# SPGSS2_1.0 register map
Vendor: Texas Instruments
Registers are 32-bit, read-write, no defined reset value unless marked. A register's access mark holds for its fields unless they carry their own. Offsets are as the file gives them; [hi:lo] are bit positions; lines under a group give offsets from that group; {n}, {i} and the like mark numbered series; 'fields as' and 'values as' point back to an identical list; <NAME> marks a mode.

## SPGSS2 (part 2 of 4)
0x7020 SPGSS2_UC3_UART_IPSTANDARD_CPU_INT group
  0x00 SPGSS2_UC3_UART_IPSTANDARD_IIDX ro — Interrupt index
    [7:0] STAT — UART Module Interrupt Vector Value. This register provides the highes priority interrupt index. A read clears the corresponding interrupt flag in RIS and MIS registers. 15h-1Fh = Reserved
      0=NO_INTR (No interrupt pending); 1=RTFG (UART receive time-out interrupt; Interrupt Flag: RT; Interrupt Priority: Highest); 2=FEFG (UART framing error interrupt; Interrupt Flag: FE); 3=PEFG (UART parity error interrupt; Interrupt Flag: PE); 4=BEFG (UART break error interrupt; Interrupt Flag: BE); 5=OEFG (UART receive overrun error interrupt; Interrupt Flag: OE); 6=RXNE (Negative edge on UARTxRXD interrupt; Interrupt Flag: RXNE); 7=RXPE (Positive edge on UARTxRXD interrupt; Interrupt Flag: RXPE); 8=LINC0 (LIN capture 0 / match interrupt; Interrupt Flag: LINC0); 9=LINC1 (LIN capture 1 interrupt; Interrupt Flag: LINC1); 10=LINOVF (LIN hardware counter overflow interrupt; Interrupt Flag: LINOVF); 11=RXIFG (UART receive interrupt; Interrupt Flag: RX); 12=TXIFG (UART transmit interrupt; Interrupt Flag: TX); 13=EOT (UART end of transmission interrupt (transmit serializer empty); Interrupt Flag: EOT); 14=ADDR_MATCH (9-bit mode address match interrupt; Interrupt Flag: ADDR_MATCH); 15=CTS (UART Clear to Send Modem interrupt; Interrupt Flag: CTS); 16=DMA_DONE_RX (DMA DONE on RX); 17=DMA_DONE_TX (DMA DONE on TX); 18=NERR_EVT (Noise Error Event); 19=DMA_PREIRQ_RX (DMA PRE IRQ INTERRUPT); 20=DMA_PREIRQ_TX (DMA PRE IRQ INTERRUPT); 21=LTFG (UART line time-out interrupt; Interrupt Flag)
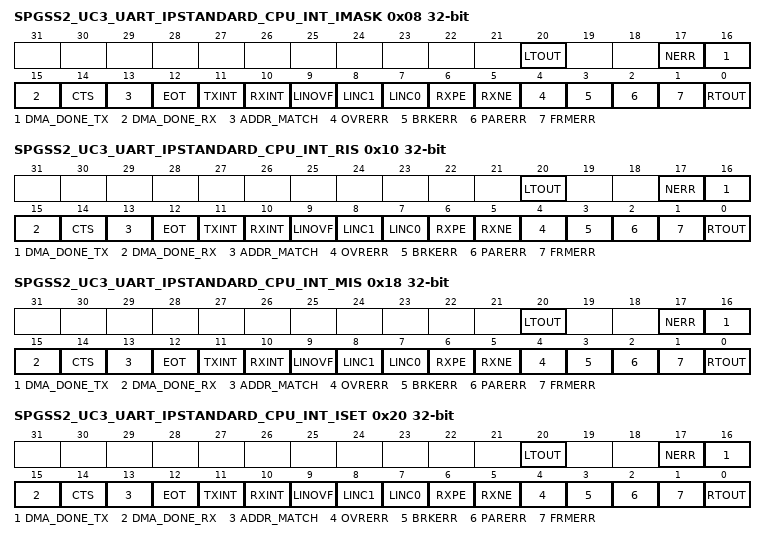
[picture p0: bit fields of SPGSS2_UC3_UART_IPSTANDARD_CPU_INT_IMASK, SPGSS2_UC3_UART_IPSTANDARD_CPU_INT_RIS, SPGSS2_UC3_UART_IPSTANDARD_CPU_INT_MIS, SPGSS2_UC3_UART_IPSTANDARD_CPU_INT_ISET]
  0x08 SPGSS2_UC3_UART_IPSTANDARD_CPU_INT_IMASK — Interrupt mask
    [20] LTOUT — Enable UARTOUT Line Time-Out Interrupt.
      0=CLR (Clear Interrupt Mask); 1=SET (Set Interrupt Mask)
    [17] NERR — Noise Error on triple voting. Asserted when the 3 samples of majority voting are not equal
      0=CLR (Clear Interrupt Mask); 1=SET (Set Interrupt Mask)
    [16] DMA_DONE_TX — Enable DMA Done on TX Event Channel Interrupt
      0=CLR (Interrupt disabled); 1=SET (Set Interrupt Mask)
    [15] DMA_DONE_RX — Enable DMA Done on RX Event Channel Interrupt
      0=CLR (Interrupt disabled); 1=SET (Set Interrupt Mask)
    [14] CTS — Enable UART Clear to Send Modem Interrupt.
      0=CLR (Interrupt disabled); 1=SET (Set Interrupt Mask)
    [13] ADDR_MATCH — Enable Address Match Interrupt.
      0=CLR (Clear Interrupt Mask); 1=SET (Set Interrupt Mask)
    [12] EOT — Enable UART End of Transmission Interrupt Indicates that the last bit of all transmitted data and flags has left the serializer and without any further Data in the TX Fifo or Buffer.
      0=CLR (Clear Interrupt Mask); 1=SET (Set Interrupt Mask)
    [11] TXINT — Enable UART Transmit Interrupt.
      0=CLR (Clear Interrupt Mask); 1=SET (Set Interrupt Mask)
    [10] RXINT — Enable UART Receive Interrupt.
      0=CLR (Clear Interrupt Mask); 1=SET (Set Interrupt Mask)
    [9] LINOVF — Enable LIN Hardware Counter Overflow Interrupt.
      0=CLR (Clear Interrupt Mask); 1=SET (Set Interrupt Mask)
    [8] LINC1 — Enable LIN Capture 1 Interrupt.
      0=CLR (Clear Interrupt Mask); 1=SET (Set Interrupt Mask)
    [7] LINC0 — Enable LIN Capture 0 / Match Interrupt .
      0=CLR (Clear Interrupt Mask); 1=SET (Set Interrupt Mask)
    [6] RXPE — Enable Positive Edge on UARTxRXD Interrupt.
      0=CLR (Clear Interrupt Mask); 1=SET (Set Interrupt Mask)
    [5] RXNE — Enable Negative Edge on UARTxRXD Interrupt.
      0=CLR (Clear Interrupt Mask); 1=SET (Set Interrupt Mask)
    [4] OVRERR — Enable UART Receive Overrun Error Interrupt.
      0=CLR (Clear Interrupt Mask); 1=SET (Set Interrupt Mask)
    [3] BRKERR — Enable UART Break Error Interrupt.
      0=CLR (Clear Interrupt Mask); 1=SET (Set Interrupt Mask)
    [2] PARERR — Enable UART Parity Error Interrupt.
      0=CLR (Clear Interrupt Mask); 1=SET (Set Interrupt Mask)
    [1] FRMERR — Enable UART Framing Error Interrupt.
      0=CLR (Clear Interrupt Mask); 1=SET (Set Interrupt Mask)
    [0] RTOUT — Enable UARTOUT Receive Time-Out Interrupt.
      0=CLR (Clear Interrupt Mask); 1=SET (Set Interrupt Mask)
  0x10 SPGSS2_UC3_UART_IPSTANDARD_CPU_INT_RIS — Raw interrupt status
    [20] LTOUT — UARTOUT Line Time-Out Interrupt. Set: no start edge has been detected for an additional character period after reception of last character. This is irrespective of FIFO contents Clear: timeout has not occured
      0=CLR (Interrupt did not occur); 1=SET (Interrupt occurred)
    [17] NERR — Noise Error on triple voting. Asserted when the 3 samples of majority voting are not equal
      0=CLR (Interrupt did not occur); 1=SET (Interrupt occurred)
    [16] DMA_DONE_TX — DMA Done on TX Event Channel Interrupt
      0=CLR (Interrupt disabled); 1=SET (Interrupt occurred)
    [15] DMA_DONE_RX — DMA Done on RX Event Channel Interrupt
      0=CLR (Interrupt disabled); 1=SET (Interrupt occurred)
    [14] CTS — UART Clear to Send Modem Interrupt. This interrupt is raised when CTS toggles, either from '0' to '1' or from '1' to '0'.
      0=CLR (Interrupt disabled); 1=SET (Interrupt occurred)
    [13] ADDR_MATCH — Address Match Interrupt.
      0=CLR (Interrupt did not occur); 1=SET (Interrupt occurred)
    [12] EOT — UART End of Transmission Interrupt Indicates that the last bit of all transmitted data and flags has left the serializer and without any further Data in the TX Fifo or Buffer.
      0=CLR (Interrupt did not occur); 1=SET (Interrupt occurred)
    [11] TXINT — UART Transmit Interrupt.
      0=CLR (Interrupt did not occur); 1=SET (Interrupt occurred)
    [10] RXINT — UART Receive Interrupt.
      0=CLR (Interrupt did not occur); 1=SET (Interrupt occurred)
    [9] LINOVF — LIN Hardware Counter Overflow Interrupt.
      0=CLR (Interrupt did not occur); 1=SET (Interrupt occurred)
    [8] LINC1 — LIN Capture 1 Interrupt.
      0=CLR (Interrupt did not occur); 1=SET (Interrupt occurred)
    [7] LINC0 — LIN Capture 0 / Match Interrupt .
      0=CLR (Interrupt did not occur); 1=SET (Interrupt occurred)
    [6] RXPE — Positive Edge on UARTxRXD Interrupt.
      0=CLR (Interrupt did not occur); 1=SET (Interrupt occurred)
    [5] RXNE — Negative Edge on UARTxRXD Interrupt.
      0=CLR (Interrupt did not occur); 1=SET (Interrupt occurred)
    [4] OVRERR — UART Receive Overrun Error Interrupt. UART Receive Overrun Error Interrupt is raised when the receive FIFO is flow and a new frame is received
      0=CLR (Interrupt did not occur); 1=SET (Interrupt occurred)
    [3] BRKERR — UART Break Error Interrupt. Break Error Interrupt is raised when all data bits, parity bit and stop bits are '0'
      0=CLR (Interrupt did not occur); 1=SET (Interrupt occurred)
    [2] PARERR — UART Parity Error Interrupt.
      0=CLR (Interrupt did not occur); 1=SET (Interrupt occurred)
    [1] FRMERR — UART Framing Error Interrupt. Framing error interrupt is raised when a "low" stop bit is detected.
      0=CLR (Interrupt did not occur); 1=SET (Interrupt occurred)
    [0] RTOUT — UARTOUT Receive Time-Out Interrupt. Interupt is raised when a time-out has lapsed and there are still items in the FIFO
      0=CLR (Interrupt did not occur); 1=SET (Interrupt occurred)
  0x18 SPGSS2_UC3_UART_IPSTANDARD_CPU_INT_MIS — Masked interrupt status
    [all] fields
      0=CLR (Interrupt did not occur); 1=SET (Interrupt occurred)
    [20] LTOUT — Masked UARTOUT Line Time-Out Interrupt.
    [17] NERR — Noise Error on triple voting. Asserted when the 3 samples of majority voting are not equal
    [16] DMA_DONE_TX — Masked DMA Done on TX Event Channel Interrupt
    [15] DMA_DONE_RX — Masked DMA Done on RX Event Channel Interrupt
    [14] CTS — Masked UART Clear to Send Modem Interrupt.
    [13] ADDR_MATCH — Masked Address Match Interrupt.
    [12] EOT — UART End of Transmission Interrupt Indicates that the last bit of all transmitted data and flags has left the serializer and without any further Data in the TX Fifo or Buffer.
    [11] TXINT — Masked UART Transmit Interrupt.
    [10] RXINT — Masked UART Receive Interrupt.
    [9] LINOVF — Masked LIN Hardware Counter Overflow Interrupt.
    [8] LINC1 — Masked LIN Capture 1 Interrupt.
    [7] LINC0 — Masked LIN Capture 0 / Match Interrupt .
    [6] RXPE — Masked Positive Edge on UARTxRXD Interrupt.
    [5] RXNE — Masked Negative Edge on UARTxRXD Interrupt.
    [4] OVRERR — Masked UART Receive Overrun Error Interrupt.
    [3] BRKERR — Masked UART Break Error Interrupt.
    [2] PARERR — Masked UART Parity Error Interrupt.
    [1] FRMERR — Masked UART Framing Error Interrupt.
    [0] RTOUT — Masked UARTOUT Receive Time-Out Interrupt.
  0x20 SPGSS2_UC3_UART_IPSTANDARD_CPU_INT_ISET — Interrupt set
    [20] LTOUT — Set UARTOUT Line Time-Out Interrupt.
      0=NO_EFFECT (Writing 0 has no effect); 1=SET (Set Interrupt)
    [17] NERR — Noise Error on triple voting. Asserted when the 3 samples of majority voting are not equal
      0=NO_EFFECT (Writing this has no effect); 1=SET (Set the interrupt)
    [16] DMA_DONE_TX — Set DMA Done on TX Event Channel Interrupt
      0=NO_EFFECT (Interrupt disabled); 1=SET (Set Interrupt)
    [15] DMA_DONE_RX — Set DMA Done on RX Event Channel Interrupt
      0=NO_EFFECT (Interrupt disabled); 1=SET (Set Interrupt)
    [14] CTS — Set UART Clear to Send Modem Interrupt.
      0=NO_EFFECT (Writing 0 has no effect); 1=SET (Set Interrupt)
    [13] ADDR_MATCH — Set Address Match Interrupt.
      0=NO_EFFECT (Writing 0 has no effect); 1=SET (Set Interrupt)
    [12] EOT — Set UART End of Transmission Interrupt Indicates that the last bit of all transmitted data and flags has left the serializer and without any further Data in the TX Fifo or Buffer.
      0=NO_EFFECT (Writing 0 has no effect); 1=SET (Set Interrupt)
    [11] TXINT — Set UART Transmit Interrupt.
      0=NO_EFFECT (Writing 0 has no effect); 1=SET (Set Interrupt)
    [10] RXINT — Set UART Receive Interrupt.
      0=NO_EFFECT (Writing 0 has no effect); 1=SET (Set Interrupt)
    [9] LINOVF — Set LIN Hardware Counter Overflow Interrupt.
      0=NO_EFFECT (Writing 0 has no effect); 1=SET (Set Interrupt)
    [8] LINC1 — Set LIN Capture 1 Interrupt.
      0=NO_EFFECT (Writing 0 has no effect); 1=SET (Set Interrupt)
    [7] LINC0 — Set LIN Capture 0 / Match Interrupt .
      0=NO_EFFECT (Writing 0 has no effect); 1=SET (Set Interrupt)
    [6] RXPE — Set Positive Edge on UARTxRXD Interrupt.
      0=NO_EFFECT (Writing 0 has no effect); 1=SET (Set Interrupt)
    [5] RXNE — Set Negative Edge on UARTxRXD Interrupt.
      0=NO_EFFECT (Writing 0 has no effect); 1=SET (Set Interrupt)
    [4] OVRERR — Set UART Receive Overrun Error Interrupt.
      0=NO_EFFECT (Writing 0 has no effect); 1=SET (Set Interrupt)
    [3] BRKERR — Set UART Break Error Interrupt.
      0=NO_EFFECT (Writing 0 has no effect); 1=SET (Set Interrupt)
    [2] PARERR — Set UART Parity Error Interrupt.
      0=NO_EFFECT (Writing 0 has no effect); 1=SET (Set Interrupt)
    [1] FRMERR — Set UART Framing Error Interrupt.
      0=NO_EFFECT (Writing 0 has no effect); 1=SET (Set Interrupt)
    [0] RTOUT — Set UARTOUT Receive Time-Out Interrupt.
      0=NO_EFFECT (Writing 0 has no effect); 1=SET (Set Interrupt)
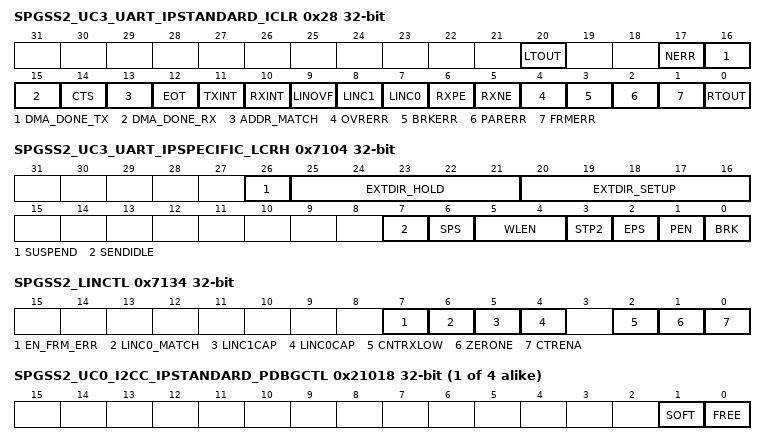
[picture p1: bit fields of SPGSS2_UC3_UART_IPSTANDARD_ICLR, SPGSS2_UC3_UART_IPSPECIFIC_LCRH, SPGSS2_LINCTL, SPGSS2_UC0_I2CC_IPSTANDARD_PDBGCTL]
  0x28 SPGSS2_UC3_UART_IPSTANDARD_ICLR — Interrupt clear
    [20] LTOUT — Clear UARTOUT Line Time-Out Interrupt.
      0=NO_EFFECT (Writing 0 has no effect); 1=CLR (Clear Interrupt)
    [17] NERR — Noise Error on triple voting. Asserted when the 3 samples of majority voting are not equal
      values as LTOUT
    [16] DMA_DONE_TX — Clear DMA Done on TX Event Channel Interrupt
      0=NO_EFFECT (Interrupt disabled); 1=CLR (Clear Interrupt)
    [15] DMA_DONE_RX — Clear DMA Done on RX Event Channel Interrupt
      0=NO_EFFECT (Interrupt disabled); 1=CLR (Clear Interrupt)
    [14] CTS — Clear UART Clear to Send Modem Interrupt.
      values as LTOUT
    [13] ADDR_MATCH — Clear Address Match Interrupt.
      values as LTOUT
    [12] EOT — Clear UART End of Transmission Interrupt Indicates that the last bit of all transmitted data and flags has left the serializer and without any further Data in the TX Fifo or Buffer.
      values as LTOUT
    [11] TXINT — Clear UART Transmit Interrupt.
      values as LTOUT
    [10] RXINT — Clear UART Receive Interrupt.
      values as LTOUT
    [9] LINOVF — Clear LIN Hardware Counter Overflow Interrupt.
      values as LTOUT
    [8] LINC1 — Clear LIN Capture 1 Interrupt.
      values as LTOUT
    [7] LINC0 — Clear LIN Capture 0 / Match Interrupt .
      values as LTOUT
    [6] RXPE — Clear Positive Edge on UARTxRXD Interrupt.
      values as LTOUT
    [5] RXNE — Clear Negative Edge on UARTxRXD Interrupt.
      values as LTOUT
    [4] OVRERR — Clear UART Receive Overrun Error Interrupt.
      values as LTOUT
    [3] BRKERR — Clear UART Break Error Interrupt.
      values as LTOUT
    [2] PARERR — Clear UART Parity Error Interrupt.
      values as LTOUT
    [1] FRMERR — Clear UART Framing Error Interrupt.
      values as LTOUT
    [0] RTOUT — Clear UARTOUT Receive Time-Out Interrupt.
      values as LTOUT
0x7104 SPGSS2_UC3_UART_IPSPECIFIC_LCRH — UART Line Control Register
  [26] SUSPEND — Suspend external communication
    0=DISABLE (Functional mode resumed); 1=ENABLE (External communication suspended)
  [25:21] EXTDIR_HOLD — Defines the number of UARTclk ticks the signal to control the external driver for the RS485 will be reset after the beginning of the stop bit. (If 2 STOP bits are enabled the beginning of the 2nd STOP bit.)
    0=MINIMUM (Smallest value); 31=MAXIMUM (Highest possible value)
  [20:16] EXTDIR_SETUP — Defines the number of UARTclk ticks the signal to control the external driver for the RS485 will be set before the START bit is send
    values as EXTDIR_HOLD
  [7] SENDIDLE — UART send IDLE pattern. When this bit is set, SENDIDLE period of 11 bit times will be sent on the TX line. Read STAT.SENDIDLE bit to readback current status of SENDIDLE
    0=DISABLE (Normal operation); 1=ENABLE (Send Idle Pattern)
  [6] SPS — UART Stick Parity Select The Stick Parity Select (SPS) bit is used to set either a permanent '1' or a permanent '0' as parity when transmitting or receiving data. Its purpose is to typically indicate the first byte of a package or to mark an address byte, for example in a multi-drop RS-485 network. When bits PEN, EPS, and SPS of UARTLCRH are set, the parity bit is transmitted and checked as a 0. When bits PEN and SPS are set and EPS is cleared, the parity bit is transmitted and checked as a 1.
    0=DISABLE (Disable Stick Parity); 1=ENABLE (Enable Stick Parity)
  [5:4] WLEN — UART Word Length The bits indicate the number of data bits transmitted or received in a frame as follows:
    0=DATABIT5 (5 bits (default)); 1=DATABIT6 (6 bits); 2=DATABIT7 (7 bits); 3=DATABIT8 (8 bits)
  [3] STP2 — UART Two Stop Bits Select When in 7816 smart card mode (the SMART bit is set in the UARTCTL register), the number of stop bits is forced to 2.
    0=DISABLE (One stop bit is transmitted at the end of a frame.); 1=ENABLE (Two stop bits are transmitted at the end of a frame. The receive logic checks for two stop bits being received and provide Frame Error if either is invalid.)
  [2] EPS — UART Even Parity Select This bit has no effect when parity is disabled by the PEN bit. For 9-Bit UART Mode transmissions, this bit controls the address byte and data byte indication (9th bit). 0 = The transferred byte is a data byte 1 = The transferred byte is an address byte
    0=ODD (Odd parity is performed, which checks for an odd number of 1s.); 1=EVEN (Even parity generation and checking is performed during transmission and reception, which checks for an even number of 1s in data and parity bits.)
  [1] PEN — UART Parity Enable
    0=DISABLE (Parity is disabled and no parity bit is added to the data frame.); 1=ENABLE (Parity checking and generation is enabled.)
  [0] BRK — UART Send Break (for LIN Protocol) 1. Break condition is sent on the line for as long as this bit is set
    0=DISABLE (Normal operation); 1=ENABLE (A low level is continually output on the UARTxTXD signal, after completing transmission of the current character. For the proper execution of the break command, software must set this bit for at least two frames (character periods).)
0x7130 SPGSS2_LINCNT — UART LIN Mode Counter Register
  [15:0] VALUE — 16 bit up counter clocked by the functional clock of the UART.
    0=MINIMUM (Smallest value); 0xFFFF=MAXIMUM (Highest possible value)
0x7134 SPGSS2_LINCTL — UART LIN Mode Control Register
  [7] EN_FRM_ERR — Enable FRAME ERROR
    0=DISABLE (Disable Frame Error Generation If STOP bit of '0' is received, then, FRAME ERROR is not generated); 1=ENABLE (Enable Frame Error Generation If STOP bit of '0' is received, then, FRAME ERROR is generated)
  [6] LINC0_MATCH — Counter Compare Match Mode When this bit is set to 1 a counter compare match with LINC0 register triggers an LINC0 interrupt when enabled.
    0=DISABLE (Counter compare match mode disabled (capture mode enabled)); 1=ENABLE (Counter compare match enabled (capture mode disabled))
  [5] LINC1CAP — Capture Counter on positive RXD Edge. When enabled the counter value is captured to LINC1 register on each positive RXD edge. A LINC1 interrupt is triggered when enabled.
    0=DISABLE (Capture counter on positive UARTxRXD edge disabled); 1=ENABLE (Capture counter on positive UARTxRXD edge enabled)
  [4] LINC0CAP — Capture Counter on negative RXD Edge. When enabled the counter value is captured to LINC0 register on each negative RXD edge. A LINC0 interrupt is triggered when enabled.
    0=DISABLE (Capture counter on negative UARTxRXD edge disabled); 1=ENABLE (Capture counter on negative UARTxRXD edge enabled)
  [2] CNTRXLOW — Count while low Signal on RXD When counter is enabled and the signal on RXD is low, the counter increments.
    0=DISABLE (Count while low Signal on UARTxRXD disabled); 1=ENABLE (Count while low Signal on UARTxRXD enabled)
  [1] ZERONE — Zero on negative Edge of RXD. When enabled the counter is set to 0 and starts counting on a negative edge of RXD
    0=DISABLE (Zero on negative edge disabled); 1=ENABLE (Zero on negative edge enabled)
  [0] CTRENA — LIN Counter Enable. LIN counter will only count when enabled.
    0=DISABLE (Counter disabled); 1=ENABLE (Counter enabled)
0x7138 SPGSS2_LINC0 — UART LIN Mode Capture 0 Register
  [15:0] DATA — 16 Bit Capture / Compare Register Captures current LINCTR value on RXD falling edge and can generate a LINC0 interrupt when capture is enabled (LINC0CAP = 1). If compare mode is enabled (LINC0_MATCH = 1), a counter match can generate a LINC0 interrupt.
    values as SPGSS2_LINCNT.VALUE
0x713C SPGSS2_LINC1 — UART LIN Mode Capture 1 Register
  [15:0] DATA — 16 Bit Capture / Compare Register Captures current LINCTR value on RXD rising edge and can generate a LINC1 interrupt when capture is enabled (LINC1CAP = 1)
    values as SPGSS2_LINCNT.VALUE
{0x21000+0x2000*i} SPGSS2_UC{i}_I2CC_IPSTANDARD_CLKDIV (i=0..3) — Clock Divider
  [2:0] RATIO — Selects divide ratio of module clock Division factor 0 : DIV_BY_1 1 : DIV_BY_2 .... 63: DIV_BY_64
{0x21008+0x2000*i} SPGSS2_UC{i}_I2CC_IPSTANDARD_CLKSEL (i=0..3) — Clock Select for Ultra Low Power peripherals
  [3] BUSCLK_SEL — Selects BUS CLK as clock source if enabled
    0=DISABLE (Does not select this clock as a source); 1=ENABLE (Select this clock as a source)
{0x21018+0x2000*i} SPGSS2_UC{i}_I2CC_IPSTANDARD_PDBGCTL (i=0..3) — Peripheral Debug Control
  [1] SOFT — Soft halt boundary control. This function is only available, if [FREE] is set to 'STOP'
    0=DEPRECATED (Not supported); 1=DELAYED (The peripheral blocks the debug freeze until it has reached a boundary where it can resume without corruption)
  [0] FREE — Free run control
    0=STOP (The peripheral freezes functionality while the Core Halted input is asserted and resumes when it is deasserted.); 1=RUN (The peripheral ignores the state of the Core Halted input)
{0x21020+0x2000*i} SPGSS2_UC{i}_I2CC_IPSTANDARD_CPU_INT group (i=0..2)
  0x00 SPGSS2_UC{i}_I2CC_IPSTANDARD_IIDX ro — Interrupt index
    [7:0] STAT — I2C Module Interrupt Vector Value. This register provides the highes priority interrupt index. A read clears the corresponding interrupt flag in RIS and MISC. 15h-1Fh = Reserved
      0=NO_INTR (No interrupt pending); 1=RXDONEFG (Data received); 2=TXDONEFG (data transmitted); 3=RXTRG (Receive Trigger); 4=TXTRG (Transmit Trigger); 5=RXFULL (RX FIFO FULL Event/interrupt pending); 6=TXEMPTY (Transmit FIFO/Buffer Empty Event/interrupt pending); 8=NACKFG (Address/Data NACK); 9=STARTFG (Start Event); 10=STOPFG (Stop Event); 11=ARBLOSTFG (Arbitration Lost); 12=PEC_RX_ERR (PEC Receive Error Event); 13=TIMEOUTA (Timeout A Event); 14=TIMEOUTB (Timeout B Event); 16=DMA_DONE_RX (DMA DONE on Channel RX); 17=DMA_DONE_TX (DMA DONE on Channel TX); 19=DMA_PREIRQ_RX (DMA PRE IRQ INTERRUPT); 20=DMA_PREIRQ_TX (DMA PRE IRQ INTERRUPT)
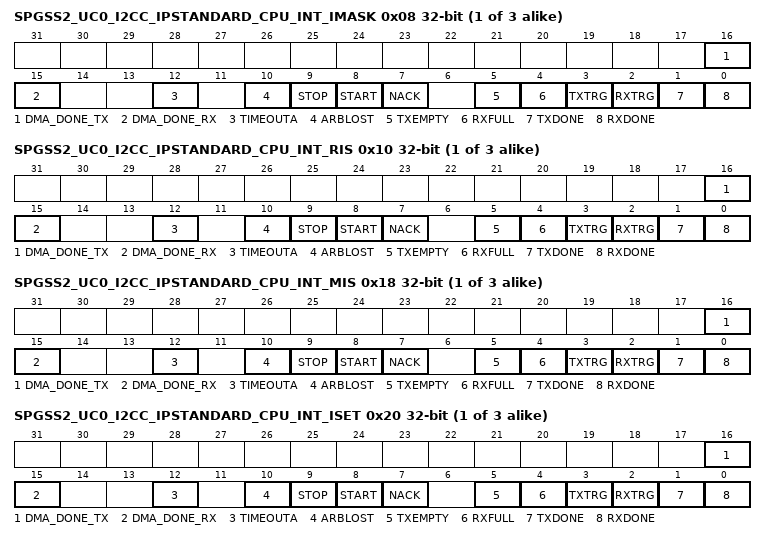
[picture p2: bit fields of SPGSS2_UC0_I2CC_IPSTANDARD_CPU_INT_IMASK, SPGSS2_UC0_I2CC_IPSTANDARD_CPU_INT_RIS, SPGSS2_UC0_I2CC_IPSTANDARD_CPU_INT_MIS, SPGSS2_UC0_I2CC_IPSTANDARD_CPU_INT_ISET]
  0x08 SPGSS2_UC{i}_I2CC_IPSTANDARD_CPU_INT_IMASK — Interrupt mask
    [16] DMA_DONE_TX — DMA Done on Event Channel TX
      0=CLR (Interrupt disabled); 1=SET (Set Interrupt Mask)
    [15] DMA_DONE_RX — DMA Done on Event Channel RX
      0=CLR (Interrupt disabled); 1=SET (Set Interrupt Mask)
    [12] TIMEOUTA — TIMEOUTA interrupt
      0=CLR (Clear Interrupt Mask); 1=SET (Set Interrupt Mask)
    [10] ARBLOST — Arbitration Lost interrupt
      0=CLR (Clear Interrupt Mask); 1=SET (Set Interrupt Mask)
    [9] STOP — STOP interrupt
      0=CLR (Clear Interrupt Mask); 1=SET (Set Interrupt Mask)
    [8] START — START interrupt
      0=CLR (Clear Interrupt Mask); 1=SET (Set Interrupt Mask)
    [7] NACK — NACK interrupt
      0=CLR (Clear Interrupt Mask); 1=SET (Set Interrupt Mask)
    [5] TXEMPTY — Transmit FIFO/Buffer Empty interrupt.
      0=CLR (Clear Interrupt Mask); 1=SET (Set Interrupt Mask)
    [4] RXFULL — RXFIFO full event
      0=CLR (Clear Interrupt Mask); 1=SET (Set Interrupt Mask)
    [3] TXTRG — Transmit Trigger
      0=CLR (Clear Interrupt Mask); 1=SET (Set Interrupt Mask)
    [2] RXTRG — Receive Trigger
      0=CLR (Clear Interrupt Mask); 1=SET (Set Interrupt Mask)
    [1] TXDONE — Transmit Transaction completed Interrupt
      0=CLR (Clear Interrupt Mask); 1=SET (Set Interrupt Mask)
    [0] RXDONE — RXDONE interrupt
      0=CLR (Clear Interrupt Mask); 1=SET (Set Interrupt Mask)
  0x10 SPGSS2_UC{i}_I2CC_IPSTANDARD_CPU_INT_RIS — Raw interrupt status
    [16] DMA_DONE_TX — DMA Done on Event Channel TX
      0=CLR (Interrupt disabled); 1=SET (Set Interrupt Mask)
    [15] DMA_DONE_RX — DMA Done on Event Channel RX
      0=CLR (Interrupt disabled); 1=SET (Set Interrupt Mask)
    [12] TIMEOUTA — Timeout A Interrupt
      0=CLR (Interrupt did not occur); 1=SET (Set Interrupt Mask)
    [10] ARBLOST — Arbitration Lost Interrupt: in multi-controller systems, when this controller loses out during arbitration
      0=CLR (Interrupt did not occur); 1=SET (Set Interrupt Mask)
    [9] STOP — STOP Detection Interrupt
      0=CLR (Interrupt did not occur); 1=SET (Set Interrupt Mask)
    [8] START — START Detection Interrupt
      0=CLR (Interrupt did not occur); 1=SET (Set Interrupt Mask)
    [7] NACK — Address/Data NACK Interrupt: set when address or data nack is received
      0=CLR (Interrupt did not occur); 1=SET (Set Interrupt Mask)
    [5] TXEMPTY — Transmit FIFO Empty: set when Transmit FIFO is empty
      0=CLR (Interrupt did not occur); 1=SET (Interrupt occured)
    [4] RXFULL — RXFIFO full event. This interrupt is set when receive FIFO is full.
      0=CLR (Interrupt did not occur); 1=SET (Interrupt occured)
    [3] TXTRG — Transmit Trigger When FIFO is present, as per IFLS settings When FIFO is not present, trigger when transmit buffer is empty
      0=CLR (Clear Interrupt Mask); 1=SET (Set Interrupt Mask)
    [2] RXTRG — Receive Trigger When FIFO is present, as per IFLS settings when FIFO is not present, this indicates when buffer is full
      0=CLR (Clear Interrupt Mask); 1=SET (Set Interrupt Mask)
    [1] TXDONE — Transmit Done Interrupt: TXDONE interrupt is raised when a burst length completes Or, in case of quick command, when a quick command with R/Wn bit set to '0'
      0=CLR (Interrupt did not occur); 1=SET (Set Interrupt Mask)
    [0] RXDONE — Receive Done Interrupt: RXDONE interrupt is raised when a burst length completes Or, in case of quick command, when a quick command with R/Wn bit set to '1'
      0=CLR (Interrupt did not occur); 1=SET (Set Interrupt Mask)
  0x18 SPGSS2_UC{i}_I2CC_IPSTANDARD_CPU_INT_MIS — Masked interrupt status
    [16] DMA_DONE_TX — DMA Done on Event Channel TX
      0=CLR (Interrupt disabled); 1=SET (Set Interrupt Mask)
    [15] DMA_DONE_RX — DMA Done on Event Channel RX
      0=CLR (Interrupt disabled); 1=SET (Set Interrupt Mask)
    [12] TIMEOUTA — Timeout A Interrupt
      0=CLR (Interrupt did not occur); 1=SET (Set Interrupt Mask)
    [10] ARBLOST — Arbitration Lost Interrupt
      0=CLR (Interrupt did not occur); 1=SET (Set Interrupt Mask)
    [9] STOP — STOP Detection Interrupt
      0=CLR (Interrupt did not occur); 1=SET (Set Interrupt Mask)
    [8] START — START Detection Interrupt
      0=CLR (Interrupt did not occur); 1=SET (Set Interrupt Mask)
    [7] NACK — Address/Data NACK Interrupt
      0=CLR (Interrupt did not occur); 1=SET (Set Interrupt Mask)
    [5] TXEMPTY — Transmit FIFO Empty masked interrupt. This interrupt is set if all data in the Transmit FIFO have been shifted out and the transmit goes into idle mode.
      0=CLR (Interrupt did not occur); 1=SET (Interrupt occured)
    [4] RXFULL — Masked RXFIFO full event
      0=CLR (Interrupt did not occur); 1=SET (Interrupt occured)
    [3] TXTRG — Transmit Trigger
      0=CLR (Clear Interrupt Mask); 1=SET (Set Interrupt Mask)
    [2] RXTRG — Receive Trigger
      0=CLR (Clear Interrupt Mask); 1=SET (Set Interrupt Mask)
    [1] TXDONE — Transmit Transaction completed Interrupt
      0=CLR (Interrupt did not occur); 1=SET (Set Interrupt Mask)
    [0] RXDONE — Receive Data Interrupt
      0=CLR (Interrupt did not occur); 1=SET (Set Interrupt Mask)
  0x20 SPGSS2_UC{i}_I2CC_IPSTANDARD_CPU_INT_ISET — Interrupt set
    [16] DMA_DONE_TX — DMA Done on Event Channel TX
      0=NO_EFFECT (Interrupt disabled); 1=SET (Set Interrupt Mask)
    [15] DMA_DONE_RX — DMA Done on Event Channel RX
      0=NO_EFFECT (Interrupt disabled); 1=SET (Set Interrupt Mask)
    [12] TIMEOUTA — Timeout A interrupt
      0=NO_EFFECT (Writing 0 has no effect); 1=SET (Set Interrupt Mask)
    [10] ARBLOST — Arbitration Lost Interrupt
      values as TIMEOUTA
    [9] STOP — STOP Detection Interrupt
      values as TIMEOUTA
    [8] START — START Detection Interrupt
      values as TIMEOUTA
    [7] NACK — Address/Data NACK Interrupt
      values as TIMEOUTA
    [5] TXEMPTY — Transmit FIFO Empty interrupt mask. This interrupt is set if all data in the Transmit FIFO have been shifted out and the transmit goes into idle mode.
      0=NO_EFFECT (Writing 0 has no effect); 1=SET (Set Interrupt)
    [4] RXFULL — RXFIFO full event.
      0=NO_EFFECT (Writing 0 has no effect); 1=SET (Set Interrupt)
    [3] TXTRG — Transmit Trigger
      0=NO_EFFECT (Clear Interrupt Mask); 1=SET (Set Interrupt Mask)
    [2] RXTRG — Receive Trigger
      values as TXTRG
    [1] TXDONE — Transmit Transaction completed Interrupt
      values as TIMEOUTA
    [0] RXDONE — Receive Data Interrupt Signals that a byte has been received
      values as TIMEOUTA
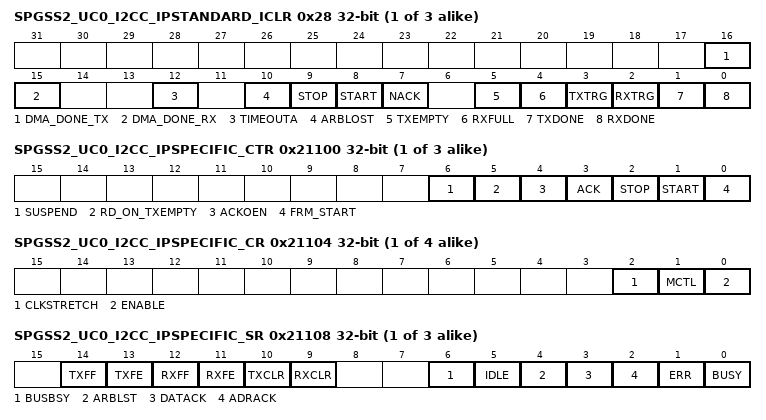
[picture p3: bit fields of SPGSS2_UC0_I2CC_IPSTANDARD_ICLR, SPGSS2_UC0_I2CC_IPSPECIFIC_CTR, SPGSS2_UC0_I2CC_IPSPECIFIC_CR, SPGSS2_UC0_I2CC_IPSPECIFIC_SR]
  0x28 SPGSS2_UC{i}_I2CC_IPSTANDARD_ICLR — Interrupt clear
    [16] DMA_DONE_TX — DMA Done on Event Channel TX
      0=NO_EFFECT (Interrupt disabled); 1=CLR (Set Interrupt Mask)
    [15] DMA_DONE_RX — DMA Done on Event Channel RX
      0=NO_EFFECT (Interrupt disabled); 1=CLR (Set Interrupt Mask)
    [12] TIMEOUTA — Timeout A interrupt
      0=NO_EFFECT (Writing 0 has no effect); 1=CLR (Set Interrupt Mask)
    [10] ARBLOST — Arbitration Lost Interrupt
      values as TIMEOUTA
    [9] STOP — STOP Detection Interrupt
      values as TIMEOUTA
    [8] START — START Detection Interrupt
      values as TIMEOUTA
    [7] NACK — Address/Data NACK Interrupt
      values as TIMEOUTA
    [5] TXEMPTY — Transmit FIFO Empty interrupt mask. This interrupt is set if all data in the Transmit FIFO have been shifted out and the transmit goes into idle mode.
      values as SPGSS2_UC3_UART_IPSTANDARD_CPU_INT.SPGSS2_UC3_UART_IPSTANDARD_ICLR.LTOUT
    [4] RXFULL — RXFIFO full event.
      values as SPGSS2_UC3_UART_IPSTANDARD_CPU_INT.SPGSS2_UC3_UART_IPSTANDARD_ICLR.LTOUT
    [3] TXTRG — Transmit FIFO Trigger
      0=NO_EFFECT (Clear Interrupt Mask); 1=CLR (Set Interrupt Mask)
    [2] RXTRG — Receive Trigger
      values as TXTRG
    [1] TXDONE — Transmit Transaction completed Interrupt
      values as TIMEOUTA
    [0] RXDONE — Receive Data Interrupt Signals that a byte has been received
      values as TIMEOUTA
{0x21050+0x2000*i} SPGSS2_UC{i}_I2CC_IPSTANDARD_DMA_TRIG1 group (i=0..3)
  0x08 SPGSS2_UC{i}_I2CC_IPSTANDARD_DMA_TRIG1_IMASK — Interrupt mask
    [2] RXTRG — Receive Trigger
      0=CLR (Clear Interrupt Mask); 1=SET (Set Interrupt Mask)
  0x10 SPGSS2_UC{i}_I2CC_IPSTANDARD_DMA_TRIG1_RIS — Raw interrupt status
    [2] RXTRG — Receive Trigger When FIFO is present, trigger when RX FIFO contains >= defined bytes when FIFO is not present, this indicates when buffer is full
      0=CLR (Clear Interrupt Mask); 1=SET (Set Interrupt Mask)
  0x18 SPGSS2_UC{i}_I2CC_IPSTANDARD_DMA_TRIG1_MIS — Masked interrupt status
    fields as SPGSS2_UC0_I2CC_IPSTANDARD_DMA_TRIG1.SPGSS2_UC{i}_I2CC_IPSTANDARD_DMA_TRIG1_IMASK
  0x20 SPGSS2_UC{i}_I2CC_IPSTANDARD_DMA_TRIG1_ISET — Interrupt set
    [2] RXTRG — Receive Trigger
      values as SPGSS2_UC0_I2CC_IPSTANDARD_CPU_INT.SPGSS2_UC{i}_I2CC_IPSTANDARD_CPU_INT_ISET.TXTRG
{0x21080+0x2000*i} SPGSS2_UC{i}_I2CC_IPSTANDARD_DMA_TRIG0 group (i=0..3)
  0x08 SPGSS2_UC{i}_I2CC_IPSTANDARD_DMA_TRIG0_IMASK — Interrupt mask
    [3] TXTRG — Transmit Trigger
      0=CLR (Clear Interrupt Mask); 1=SET (Set Interrupt Mask)
  0x10 SPGSS2_UC{i}_I2CC_IPSTANDARD_DMA_TRIG0_RIS — Raw interrupt status
    fields as SPGSS2_UC0_I2CC_IPSTANDARD_DMA_TRIG0.SPGSS2_UC{i}_I2CC_IPSTANDARD_DMA_TRIG0_IMASK
  0x18 SPGSS2_UC{i}_I2CC_IPSTANDARD_DMA_TRIG0_MIS — Masked interrupt status
    fields as SPGSS2_UC0_I2CC_IPSTANDARD_DMA_TRIG0.SPGSS2_UC{i}_I2CC_IPSTANDARD_DMA_TRIG0_IMASK
  0x20 SPGSS2_UC{i}_I2CC_IPSTANDARD_DMA_TRIG0_ISET — Interrupt set
    [3] TXTRG — Transmit Trigger
      values as SPGSS2_UC0_I2CC_IPSTANDARD_CPU_INT.SPGSS2_UC{i}_I2CC_IPSTANDARD_CPU_INT_ISET.TXTRG
{0x210E4+0x2000*i} SPGSS2_UC{i}_I2CC_IPSTANDARD_INTCTL (i=0..3) — Interrupt control register
  [0] INTEVAL — Writing a 1 to this field re-evaluates the interrupt sources.
    0=DISABLE (The interrupt or event line is disabled.); 1=EVAL (The interrupt or event line is in software mode. Software must clear the RIS.)
{0x21100+0x2000*i} SPGSS2_UC{i}_I2CC_IPSPECIFIC_CTR (i=0..2) — Control Register
  [6] SUSPEND — Suspend external communication
    values as SPGSS2_UC3_UART_IPSPECIFIC_LCRH.SUSPEND
  [5] RD_ON_TXEMPTY — Read on TX Empty
    0=DISABLE (No special behavior); 1=ENABLE (When 1 the Controller will transmit all bytes from the TX FIFO before continuing with the programmed Burst Run Read. If the DIR is not set to Read in the MSA then this bit is ignored. The Start must be set in the MCTR for proper I2C protocol. The Controller will first send the Start Condition, I2C Address with R/W bit set to write, before sending the bytes in the TX FIFO. When the TX FIFO is empty, the I2C transaction will continue as programmed in MTCR and MSA without sending a Stop Condition. This is intended to be used to perform simple I2C command based reads transition that will complete after initiating them without having to get an interrupt to turn the bus around.)
  [4] ACKOEN — ACK overrride Enable
    0=DISABLE (No special behavior); 1=ENABLE (When 1 and the Controller is receiving data and the number of bytes indicated in MBLEN have been received, the state machine will generate an rxdone interrupt and wait at the start of the ACK for FW to indicate if an ACK or NACK should be sent. The ACK or NACK is selected by writing the MCTR register and setting ACK accordingly. The other fields in this register can also be written at this time to continue on with the transaction. If a NACK is sent the state machine will automatically send a Stop.)
  [3] ACK — Data Acknowledge Enable. Software needs to configure this bit to send the ACK or NACK. See field decoding in Table: MCTR Field decoding.
    0=DISABLE (The last received data byte of a transaction is not acknowledged automatically .); 1=ENABLE (The last received data byte of a transaction is acknowledged automatically .)
  [2] STOP — Generate STOP
    0=DISABLE (The controller does not generate the STOP condition.); 1=ENABLE (The controller generates the STOP condition. See field decoding in Table: MCTR Field decoding.)
  [1] START — Generate START
    0=DISABLE (The controller does not generate the START condition.); 1=ENABLE (The controller generates the START or repeated START condition. See field decoding in Table: MCTR Field decoding.)
  [0] FRM_START — Start Transfer
    0=DISABLE (In standard mode, this encoding means the Controller is unable to transmit or receive data.); 1=ENABLE (The Controller is able to transmit or receive data. See field decoding in Table: MCTR Field decoding.)
{0x21104+0x2000*i} SPGSS2_UC{i}_I2CC_IPSPECIFIC_CR (i=0..3) — Configuration
  [2] CLKSTRETCH — Clock Stretching. This bit controls the support for clock stretching of the I2C bus.
    0=DISABLE (Disables the clock stretching detection. This can be disabled if no Target on the bus does support clock stretching, so that the maximum speed on the bus can be reached.); 1=ENABLE (Enables the clock stretching detection. Enabling the clock stretching ensures compliance to the I2C standard but could limit the speed due the clock stretching.)
  [1] MCTL — MultiController mode. In MultiController mode the SCL high time counts once the SCL line has been detected high. If this is not enabled the high time counts as soon as the SCL line has been set high by the I2C controller.
    0=DISABLE (Disable MultiController mode.); 1=ENABLE (Enable MultiController mode.)
  [0] ENABLE — Enable module. After this bit has been set, it should not be set again unless it has been cleared by writing a 0 or by a reset, otherwise transfer failures may occur.
    0=DISABLE (Disables operation.); 1=ENABLE (Enables operation.)
{0x21108+0x2000*i} SPGSS2_UC{i}_I2CC_IPSPECIFIC_SR ro (i=0..2) — Status Register
  [14] TXFF — Transmit FIFO Full The meaning of this bit depends on the state of the FEN bit in the CTL0 register.
    0=CLEARED (The transmitter is not full.); 1=SET (If the FIFO is disabled (FEN is 0), the transmit holding register is full. If the FIFO is enabled (FEN is 1), the transmit FIFO is full.)
  [13] TXFE — Transmit FIFO Empty The meaning of this bit depends on the state of the FEN bit in the CTL0 register.
    0=CLEARED (The transmitter has data to transmit.); 1=SET (If the FIFO is disabled (FEN is 0), the transmit holding register is empty. If the FIFO is enabled (FEN is 1), the transmit FIFO is empty.)
  [12] RXFF — Receive FIFO Full The meaning of this bit depends on the state of the FEN bit in the CTL0 register.
    0=CLEARED (The receiver can receive data.); 1=SET (If the FIFO is disabled (FEN is 0), the receive holding register is full. If the FIFO is enabled (FEN is 1), the receive FIFO is full.)
  [11] RXFE — Receive FIFO Empty The meaning of this bit depends on the state of the FEN bit in the CTL0 register.
    0=CLEARED (The receiver is not empty.); 1=SET (If the FIFO is disabled (FEN is 0), the receive holding register is empty. If the FIFO is enabled (FEN is 1), the receive FIFO is empty.)
  [10] TXCLR — TX FIFO Clear Status
    0=CLEARED (FIFO is not cleared); 1=SET (FIFO clear is complete)
  [9] RXCLR — RX FIFO Clear Status
    values as TXCLR
  [6] BUSBSY — I2C Bus is Busy Controller State Machine will wait until this bit to be cleared before starting a transaction. When first enabling the Controller in multi Controller environments, FW should wait for one I2C clock period after setting ACTIVE high before writing to the CTR register to start the transaction so that if SCL goes low it will trigger the BUSBSY.
    0=CLEARED (The I2C bus is idle.); 1=SET ('This Status bit is set on a START or when SCL goes low. It is cleared on a STOP, or when a SCL high bus busy timeout occurs and SCL and SDA are both high. This status is cleared when the ACTIVE bit is low. Note that the Controller State Machine will wait until this bit is cleared before starting an I2C transaction. When first enabling the Controller in multi Controller environments, FW should wait for one I2C clock period after setting ACTIVE high before writing to the MTCR register to start the transaction so that if SCL goes low it will trigger the BUSBSY.)
  [5] IDLE — I2C Idle
    0=CLEARED (The I2C controller is not idle.); 1=SET (The I2C controller is idle.)
  [4] ARBLST — Arbitration Lost
    0=CLEARED (The I2C controller won arbitration.); 1=SET (The I2C controller lost arbitration.)
  [3] DATACK — Acknowledge Data
    0=CLEARED (The transmitted data was acknowledged); 1=SET (The transmitted data was not acknowledged.)
  [2] ADRACK — Acknowledge Address
    0=CLEARED (The transmitted address was acknowledged); 1=SET (The transmitted address was not acknowledged.)
  [1] ERR — Error The error can be from the Target address not being acknowledged or the transmit data not being acknowledged.
    0=CLEARED (No error was detected on the last operation.); 1=SET (An error occurred on the last operation.)
  [0] BUSY — FSM Busy The BUSY bit is set during an ongoing transaction, so is set during the transmit/receive of the amount of data set in MBLEN including START, RESTART, Address and STOP signal generation when required for the current transaction.
    0=CLEARED (The controller is idle.); 1=SET (The controller is busy.)
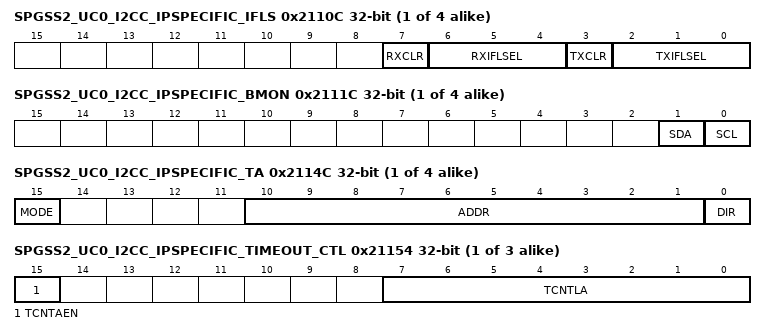
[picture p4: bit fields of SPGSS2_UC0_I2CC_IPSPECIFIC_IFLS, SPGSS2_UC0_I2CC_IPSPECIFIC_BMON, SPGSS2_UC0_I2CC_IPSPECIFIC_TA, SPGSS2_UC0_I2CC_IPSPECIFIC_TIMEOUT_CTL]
{0x2110C+0x2000*i} SPGSS2_UC{i}_I2CC_IPSPECIFIC_IFLS (i=0..3) — Interrupt FIFO Level Select Register
  [7] RXCLR — RX FIFO CLEAR. Setting this bit will clear the RX FIFO contents.
    0=DISABLE (Disable FIFO clear); 1=ENABLE (Enable FIFO Clear)
  [6:4] RXIFLSEL — FIFO Level Select for generating events (interrupt/dma). Note: for undefined settings the default configuration is used.
    1=LVL_1_4 (RX FIFO >= 1/4 full); 2=LVL_1_2 (RX FIFO >= 1/2 full (default)); 3=LVL_3_4 (RX FIFO >= 3/4 full); 4=LVL_NOT_EMPTY (Opposite of empty); 5=LVL_FULL (RX FIFO is full); 6=LVL_ALMOST_FULL (RX_FIFO >= (MAX_FIFO_LEN -1)); 7=LVL_ALMOST_EMPTY (RX_FIFO <= 1)
  [3] TXCLR — TX FIFO CLEAR. Setting this bit will clear the TX FIFO contents.
    0=DISABLE (Disable FIFO clear); 1=ENABLE (Enable FIFO Clear)
  [2:0] TXIFLSEL — FIFO Level Select for generating events (interrupt/dma). Note: for undefined settings the default configuration is used.
    1=LVL_3_4 (TX FIFO <= 3/4 empty); 2=LVL_1_2 (TX FIFO <= 1/2 empty (default)); 3=LVL_1_4 (TX FIFO <= 1/4 empty); 4=LVL_NOT_FULL (Opposite of full); 5=LVL_EMPTY (TX FIFO is empty); 6=LVL_ALMOST_EMPTY (TX FIFO <= 1); 7=LVL_ALMOST_FULL (TX_FIFO >= (MAX_FIFO_LEN -1))
{0x21110+0x2000*i} SPGSS2_UC{i}_I2CC_IPSPECIFIC_TPR (i=0..3) — Timer Period
  [6:0] TPR — Timer Period This field is used in the equation to configure SCL_PERIOD : SCL_PERIOD = (1 + TPR ) * (SCL_LP + SCL_HP ) * INT_CLK_PRD where: SCL_PRD is the SCL line period (I2C clock). TPR is the Timer Period register value (range of 1 to 127). SCL_LP is the SCL Low period (fixed at 6). SCL_HP is the SCL High period (fixed at 4). CLK_PRD is the functional clock period in ns.
    0=MINIMUM (Smallest value); 127=MAXIMUM (Highest possible value)
{0x21118+0x2000*i} SPGSS2_UC{i}_I2CC_IPSPECIFIC_GFCTL (i=0..2) — I2C Glitch Filter Control
  [2:0] DGFSEL — Glitch Suppression Pulse Width This field controls the pulse width select for glitch suppression on the SCL and SDA lines. The following values are the glitch suppression values in terms of functional clocks. (Core Domain only)
    0=DISABLED (Bypass); 1=CLK_1 (1 clock); 2=CLK_2 (2 clocks); 3=CLK_3 (3 clocks); 4=CLK_4 (4 clocks); 5=CLK_8 (8 clocks); 6=CLK_16 (16 clocks); 7=CLK_31 (31 clocks)
{0x2111C+0x2000*i} SPGSS2_UC{i}_I2CC_IPSPECIFIC_BMON ro (i=0..3) — Bus Monitor
  [1] SDA — I2C SDA Status
    0=CLEARED (The I2CSDA signal is low.); 1=SET (The I2CSDA signal is high. Note: During and right after reset, the SDA pin is in GPIO input mode without the internal pull enabled. For proper I2C operation, the user should have the external pull-up resistor in place before starting any I2C operations.)
  [0] SCL — I2C SCL Status
    0=CLEARED (The I2CSCL signal is low.); 1=SET (The I2CSCL signal is high. Note: During and right after reset, the SCL pin is in GPIO input mode without the internal pull enabled. For proper I2C operation, the user should have the external pull-up resistor in place before starting any I2C operations.)
{0x21120+0x2000*i} SPGSS2_UC{i}_I2CC_IPSPECIFIC_TXDATA (i=0..3) — TXData
  [7:0] DATA — Transmit Data This byte contains the data to be transferred during the next transaction.
    0=MINIMUM (Smallest value); 255=MAXIMUM (Highest possible value)
{0x21124+0x2000*i} SPGSS2_UC{i}_I2CC_IPSPECIFIC_RXDATA ro (i=0..3) — RXData
  [7:0] DATA — Received Data. This field contains the last received data.
    values as SPGSS2_UC0_I2CC_IPSPECIFIC_TXDATA.DATA
{0x2114C+0x2000*i} SPGSS2_UC{i}_I2CC_IPSPECIFIC_TA (i=0..3) — Target Address Register
  [15] MODE — This bit selects the adressing mode to be used When 0, 7-bit addressing is used. When 1, 10-bit addressing is used.
    0=7-bit addressing mode; 1=10-bit addressing mode
  [10:1] ADDR — I2C Target Address This field specifies bits A9 through A0 of the Target address. In 7-bit addressing mode as selected by MSA.MODE bit, the top 3 bits are don't care
    0=MINIMUM (Smallest value); 0x3FF=MAXIMUM (Highest possible value)
  [0] DIR — Receive/Send The DIR bit specifies if the next operation is a Receive (High) or Transmit (Low). 0h = Transmit 1h = Receive
    0=TRANSMIT (in transmit mode.); 1=RECEIVE (is in receive mode.)
{0x21150+0x2000*i} SPGSS2_UC{i}_I2CC_IPSPECIFIC_TIMEOUT_CNT ro (i=0..2) — I2C Timeout Count Register
  [7:0] TCNTA — Timeout Count A Current Count: This field contains the upper 8 bits of a 12-bit current counter for timeout counter A
    0=MINIMUM (Smallest Value); 255=MAXIMUM (Highest possible value)
{0x21154+0x2000*i} SPGSS2_UC{i}_I2CC_IPSPECIFIC_TIMEOUT_CTL (i=0..2) — I2C Timeout Count Control Register
  [15] TCNTAEN — Timeout Counter A Enable
    0=DISABLE (Disable Timeout Counter B); 1=ENABLE (Enable Timeout Counter B)
  [7:0] TCNTLA — Timeout counter A load value Counter A is used for SCL low detection. This field contains the upper 8 bits of a 12-bit pre-load value for the Timeout A count. NOTE: The value of CNTLA must be greater than 1h. Each count is equal to 520 times the timeout period of functional clock. For example, with 8MHz functional clock and a 100KHz operating I2C clock, one timeout period will be equal to (1 / 8MHz) * 520 or 65 us.
    values as SPGSS2_UC0_I2CC_IPSPECIFIC_TIMEOUT_CNT.TCNTA
{0x21E00+0x2000*i} SPGSS2_UC{i}_I2CC_LMGMT_DFT_ATRT_TEST0 (i=0..3) — Test 0 register
  [4:0] DTB_MUX_SEL — This bit field is used to select DTB mux digital output signals.
    0=DISABLE (Disables DTB MUX); {v}=GRP{v} (Selects test group {v}) (v=1..7)
